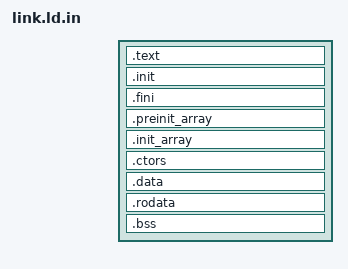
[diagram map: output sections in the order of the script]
ENTRY(_start)
OUTPUT_FORMAT("elf64-littleriscv")
SECTIONS
{
	. = %KERNEL_VIRTUAL_BASE%;
	kernel_start = .;
	. += SIZEOF_HEADERS;
	.text : AT(0x0)
	{
		*(.text*)
	}
	.init :
	{
    	KEEP (*(SORT_NONE(.init)))
	}
  	.fini :
  	{
      	KEEP (*(SORT_NONE(.fini)))
	}
  	.preinit_array :
  	{
      	PROVIDE_HIDDEN (__preinit_array_start = .);
      	KEEP (*(.preinit_array))
      	PROVIDE_HIDDEN (__preinit_array_end = .);
	}
  	.init_array :
  	{
      	PROVIDE_HIDDEN (__init_array_start = .);
      	KEEP (*(SORT(.init_array.*)))
      	KEEP (*(.init_array ))
      	PROVIDE_HIDDEN (__init_array_end = .);
	}
  	.ctors :
  	{
		KEEP (*crtbegin.o(.ctors))
		KEEP (*crtbegin?.o(.ctors))
		KEEP (*(EXCLUDE_FILE (*crtend.o *crtend?.o ) .ctors))
		KEEP (*(SORT(.ctors.*)))
		KEEP (*(.ctors))
	}
  	.data : ALIGN(0x1000)
  	{
	  	*(.data*)
      	SORT(CONSTRUCTORS)
	}

	.rodata : ALIGN(0x1000)
	{
		*(.rodata*)
		/*KEEP(*(*.debug*))*/
		KEEP(*(.ksyms*))
	}

/*
  	.debug_info     0 : { *(.debug_info .gnu.linkonce.wi.*) }
  	.debug_aranges  0 : { *(.debug_aranges) }
  	.debug_pubnames 0 : { *(.debug_pubnames) }
  	.debug_abbrev   0 : { *(.debug_abbrev) }
  	.debug_line     0 : { *(.debug_line .debug_line.* .debug_line_end ) }
  	.debug_frame    0 : { *(.debug_frame) }
  	.debug_str      0 : { *(.debug_str) }
  	.debug_loc      0 : { *(.debug_loc) }
  	.debug_macinfo  0 : { *(.debug_macinfo) }
*/
	.bss : ALIGN(0x1000)
	{
		__kernel_bss_start = .;
		*(.bss*)
		. = ALIGN(8);
		__kernel_bss_end = .;
	}

}

